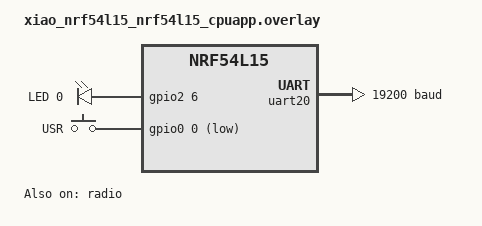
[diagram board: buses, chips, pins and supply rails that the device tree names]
/ {
	leds {
		compatible = "gpio-leds";

		led0: led_0 {
			gpios = <&gpio2 6 GPIO_ACTIVE_HIGH>;
			label = "LED 0";
		};
	};

	buttons: buttons {
		compatible = "gpio-keys";

		usr_btn: usr-btn {
			gpios = <&gpio0 0 (GPIO_PULL_UP | GPIO_ACTIVE_LOW)>;
			label = "USR";
			zephyr,code = <INPUT_KEY_ENTER>;
		};
	};

	chosen {
		ncs,dtm-uart = &uart20;
	};

	aliases {
		led0 = &led0;
		buttons = &buttons;
		sw0 = &usr_btn;
	};
};


&uart20 {
	status = "okay";
	current-speed = <19200>;
};

&radio {
	status = "okay";
	/* This is a number of antennas that are available on antenna matrix
	 * designed by Nordic. For more information see README.rst.
	 */
	dfe-antenna-num = <12>;
	/* This is a setting that enables antenna 12 (in antenna matrix designed
	 * by Nordic) for PDU. For more information see README.rst.
	 */
	dfe-pdu-antenna = <0x0>;

	/* These are GPIO pin numbers that are provided to
	 * Radio peripheral. The pins will be acquired by Radio to
	 * drive antenna switching.
	 * Pin numbers are selected to drive switches on antenna matrix
	 * desinged by Nordic. For more information see README.rst.
	 */
	dfegpio0-gpios = <&gpio0 4 0>;
	dfegpio1-gpios = <&gpio0 5 0>;
	dfegpio2-gpios = <&gpio0 6 0>;
	dfegpio3-gpios = <&gpio0 7 0>;
};
